# YTM32B1MC0 register map
Vendor: YTMicro; File version: 1.0
CPU: CM33 r0p4, little endian, MPU, FPU, 2 interrupt priority bits
Registers are 32-bit, read-write, reset 0x0 unless marked. A register's access mark holds for its fields unless they carry their own. Offsets are from the block's base; [hi:lo] are bit positions; {n}, {i} and the like mark numbered series.

## ACMP0 — Analog comparator module
Base 0x40043000; register names take the prefix ACMP0_
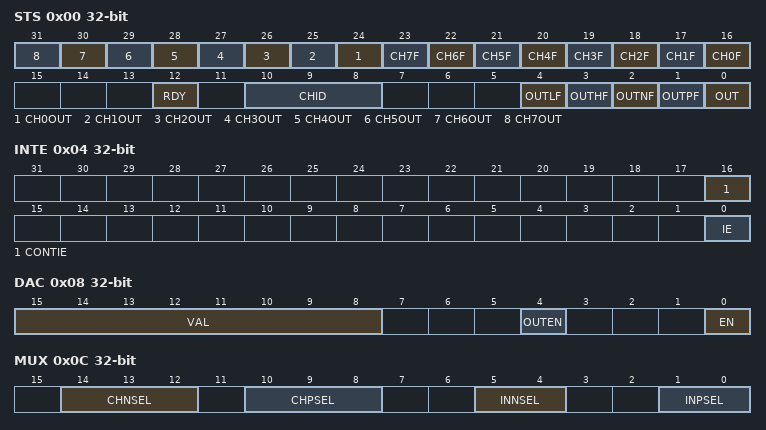
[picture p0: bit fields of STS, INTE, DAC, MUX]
0x00 STS
  [n+24] CH{n}OUT ro (n=0..7) — Indicate the channel {n} result of comparison when continuous mode enabled
    0=Indicate the channel {n} result of comparison is 0 when continuous mode enabled; 1=Indicate the channel {n} result of comparison is 1 when continuous mode enabled
  [n+16] CH{n}F (n=0..7) — In continuous mode, the flag sets when channel {n} result of comparison doesn't match with it's expected value. Write 1 to clear the flag
    0=Channel {n} result of comparison match with it's expected value; 1=Channel {n} result of comparison doesn't match with it's expected value
  [12] RDY ro — In one-shot mode, STS[RDY]=1 indicates waiting for hard trigger. When valid hard trigger got, STS[RDY] auto cleared.
  [10:8] CHID ro — Indicate current comparing channel in continuous mode
  [4] OUTLF — Comparator output Low level flag
  [3] OUTHF — Comparator output high level flag
  [2] OUTNF — Comparator output negative edge flag
  [1] OUTPF — Comparator output positive edge flag
  [0] OUT ro — Current comparator output
0x04 INTE
  [16] CONTIE — In continuous mode, interrupt occurs when INTE[CONTIE]=1 and STS[CHxF]=1
    0=Continuous mode interrupt is disabled; 1=Continuous mode interrupt is enabled
  [0] IE — Interrupt occurs when INTE[IE]=1 and STS[OUTNF]=1/STS[OUTPF]=1(depending on CTRL[EDGESEL])
    0=Interrupt is disabled; 1=Interrupt is enabled
0x08 DAC
  [15:8] VAL
  [4] OUTEN — DAC output to PIN is enabled/disabled
    0=DAC output to PIN is disabled; 1=DAC output to PIN is enabled
  [0] EN — DAC enable
    0=DAC is disabled; 1=DAC is enabled
0x0C MUX
  [14:12] CHNSEL — Select one channel as negative input of comparator
    {v}=Select channel {v} (v=0..7)
  [10:8] CHPSEL — Select one channel as positive input of comparator
    {v}=Select channel {v} (v=0..7)
  [5:4] INNSEL — Negative input of ACMP selection
    0=Select DAC output as comparator negative input; 1=Select one channel by configuring MUX[CHNSEL] as comparator negative input
  [1:0] INPSEL — Positive input of ACMP selection
    0=Select DAC output as comparator positive input; 1=Select one channel by configuring MUX[CHPSEL] as comparator positive input
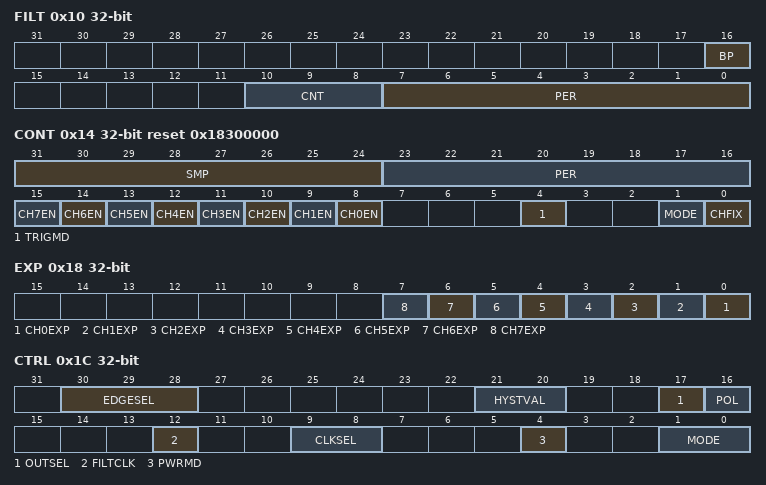
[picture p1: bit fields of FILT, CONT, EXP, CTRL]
0x10 FILT
  [16] BP — Filter bypass control
    0=Filter is not bypassed; 1=Filter is bypassed forcibly
  [10:8] CNT — Analog comparator output is regarded as a valid signal when the continuous sampling 0 or 1 reaches the configured value CNT, otherwise it is regarded as a glitch. Filter is bypassed when CNT=0
  [7:0] PER — Digital filter sampling period. Filter is bypassed when PER=0
0x14 CONT reset 0x18300000
  [31:24] SMP — After channel switching stabilization time, sample the comparator result
  [23:16] PER — The sampled channel switching period in continuous mode
  [n+8] CH{n}EN (n=0..7) — If enabled, channel {n} participates in the continuous mode
    0=Channel {n} is disabled; 1=Channel {n} is enabled
  [4] TRIGMD — Trigger mode control
    0=Trigger mode is disabled; 1=Trigger mode is enabled
  [1] MODE — Continuous mode selection
    0=Loop mode; 1=One-shot mode
  [0] CHFIX — Fix channel in continuous mode
    0=Fix negative channel, polling comparisons are made on the positive channels; 1=Fix positive channel, polling comparisons are made on the negative channels
0x18 EXP
  [all] fields
    0=The expected value is 0; 1=The expected value is 1
  [n] CH{n}EXP (n=0..7) — Channel {n} expected value configuration and write operation is valid when ACMP is disabled
0x1C CTRL
  [30:28] EDGESEL — Edge detection condition, used for interrupt and DMA request generation
    0=No edge detection; 1=Rising edge detection; 2=Falling edge detection; 3=Dual edges detection; 4=High level detection; 5=Low level detection
  [21:20] HYSTVAL — Hysteresis level selection bit
    0=Comparator hard block output has no hysteresis internally; 1=Comparator hard block output has 20mV hysteresis internally; 2=Comparator hard block output has 40mV hysteresis internally
  [17] OUTSEL — Output selection bit
    0=Send ACMP output to pin, it's up to analog circuit and work mode; 1=Send comparator raw output to pin directly(Need to consider the configuration of CTRL[POL])
  [16] POL — Output polarity selection bit
    0=Not invert comparator output; 1=Invert comparator output
  [12] FILTCLK — Filter clock source
    0=Select bus clock for filter; 1=Select function clock for filter
  [9:8] CLKSEL — Function clock selection
    0=Select function clock from IPC; 1=Select SIRC clock; 2=Select SXOSC clock; 3=Rserved
  [4] PWRMD — Power mode
    0=High speed mode; 1=Low power mode
  [1:0] MODE — ACMP function mode selection
    0=Common mode; 1=Sample mode; 2=Window mode; 3=Continuous mode
0x20 EN
  [0] EN — Module enable bit
    0=ACMP module is disabled; 1=ACMP module is enabled
0x24 DMACR
  [0] EN — Combine EDGESEL and OUTNF/OUTPF to generate DMA request
    0=DMA request is disabled; 1=DMA request is enabled
